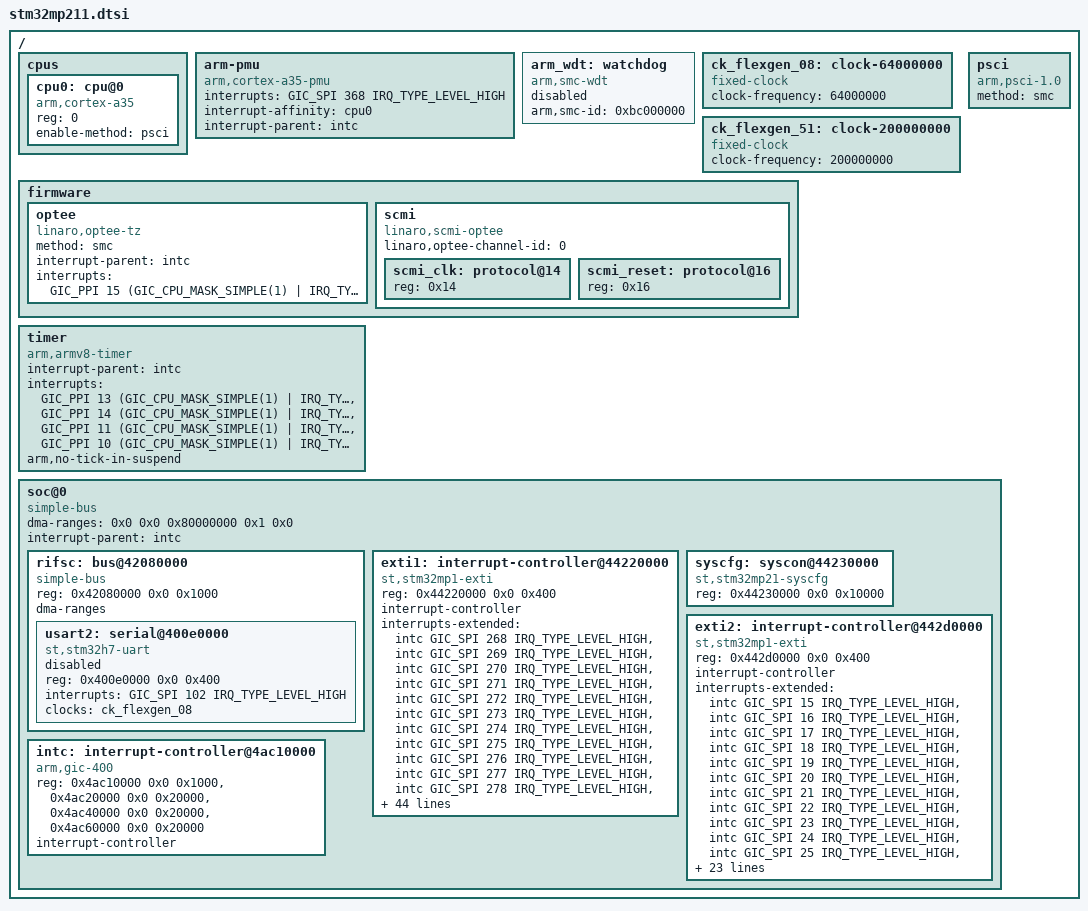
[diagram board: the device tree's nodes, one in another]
// SPDX-License-Identifier: (GPL-2.0-only OR BSD-3-Clause)
/*
 * Copyright (C) STMicroelectronics 2025 - All Rights Reserved
 * Author: Alexandre Torgue <alexandre.torgue@foss.st.com> for STMicroelectronics.
 */
#include <dt-bindings/interrupt-controller/arm-gic.h>

/ {
	#address-cells = <2>;
	#size-cells = <2>;

	cpus {
		#address-cells = <1>;
		#size-cells = <0>;

		cpu0: cpu@0 {
			compatible = "arm,cortex-a35";
			reg = <0>;
			device_type = "cpu";
			enable-method = "psci";
		};
	};

	arm-pmu {
		compatible = "arm,cortex-a35-pmu";
		interrupts = <GIC_SPI 368 IRQ_TYPE_LEVEL_HIGH>;
		interrupt-affinity = <&cpu0>;
		interrupt-parent = <&intc>;
	};

	arm_wdt: watchdog {
		compatible = "arm,smc-wdt";
		arm,smc-id = <0xbc000000>;
		status = "disabled";
	};

	ck_flexgen_08: clock-64000000 {
		compatible = "fixed-clock";
		#clock-cells = <0>;
		clock-frequency = <64000000>;
	};

	ck_flexgen_51: clock-200000000 {
		compatible = "fixed-clock";
		#clock-cells = <0>;
		clock-frequency = <200000000>;
	};

	firmware {
		optee {
			compatible = "linaro,optee-tz";
			method = "smc";
			interrupt-parent = <&intc>;
			interrupts = <GIC_PPI 15 (GIC_CPU_MASK_SIMPLE(1) | IRQ_TYPE_LEVEL_LOW)>;
		};

		scmi: scmi {
			compatible = "linaro,scmi-optee";
			#address-cells = <1>;
			#size-cells = <0>;
			linaro,optee-channel-id = <0>;

			scmi_clk: protocol@14 {
				reg = <0x14>;
				#clock-cells = <1>;
			};

			scmi_reset: protocol@16 {
				reg = <0x16>;
				#reset-cells = <1>;
			};
		};
	};

	psci {
		compatible = "arm,psci-1.0";
		method = "smc";
	};

	timer {
		compatible = "arm,armv8-timer";
		interrupt-parent = <&intc>;
		interrupts = <GIC_PPI 13 (GIC_CPU_MASK_SIMPLE(1) | IRQ_TYPE_LEVEL_LOW)>,
			     <GIC_PPI 14 (GIC_CPU_MASK_SIMPLE(1) | IRQ_TYPE_LEVEL_LOW)>,
			     <GIC_PPI 11 (GIC_CPU_MASK_SIMPLE(1) | IRQ_TYPE_LEVEL_LOW)>,
			     <GIC_PPI 10 (GIC_CPU_MASK_SIMPLE(1) | IRQ_TYPE_LEVEL_LOW)>;
		arm,no-tick-in-suspend;
	};

	soc@0 {
		compatible = "simple-bus";
		ranges = <0x0 0x0 0x0 0x0 0x80000000>;
		dma-ranges = <0x0 0x0 0x80000000 0x1 0x0>;
		interrupt-parent = <&intc>;
		#address-cells = <1>;
		#size-cells = <2>;

		rifsc: bus@42080000 {
			compatible = "simple-bus";
			reg = <0x42080000 0x0 0x1000>;
			ranges;
			dma-ranges;
			#address-cells = <1>;
			#size-cells = <2>;

			usart2: serial@400e0000 {
				compatible = "st,stm32h7-uart";
				reg = <0x400e0000 0x0 0x400>;
				interrupts = <GIC_SPI 102 IRQ_TYPE_LEVEL_HIGH>;
				clocks = <&ck_flexgen_08>;
				status = "disabled";
			};
		};

		exti1: interrupt-controller@44220000 {
			compatible = "st,stm32mp1-exti", "syscon";
			reg = <0x44220000 0x0 0x400>;
			interrupt-controller;
			#interrupt-cells = <2>;
			interrupts-extended =
				<&intc GIC_SPI 268 IRQ_TYPE_LEVEL_HIGH>,	/* EXTI_0 */
				<&intc GIC_SPI 269 IRQ_TYPE_LEVEL_HIGH>,
				<&intc GIC_SPI 270 IRQ_TYPE_LEVEL_HIGH>,
				<&intc GIC_SPI 271 IRQ_TYPE_LEVEL_HIGH>,
				<&intc GIC_SPI 272 IRQ_TYPE_LEVEL_HIGH>,
				<&intc GIC_SPI 273 IRQ_TYPE_LEVEL_HIGH>,
				<&intc GIC_SPI 274 IRQ_TYPE_LEVEL_HIGH>,
				<&intc GIC_SPI 275 IRQ_TYPE_LEVEL_HIGH>,
				<&intc GIC_SPI 276 IRQ_TYPE_LEVEL_HIGH>,
				<&intc GIC_SPI 277 IRQ_TYPE_LEVEL_HIGH>,
				<&intc GIC_SPI 278 IRQ_TYPE_LEVEL_HIGH>,	/* EXTI_10 */
				<&intc GIC_SPI 279 IRQ_TYPE_LEVEL_HIGH>,
				<&intc GIC_SPI 280 IRQ_TYPE_LEVEL_HIGH>,
				<&intc GIC_SPI 281 IRQ_TYPE_LEVEL_HIGH>,
				<&intc GIC_SPI 282 IRQ_TYPE_LEVEL_HIGH>,
				<&intc GIC_SPI 283 IRQ_TYPE_LEVEL_HIGH>,
				<&intc GIC_SPI 0   IRQ_TYPE_LEVEL_HIGH>,
				<&intc GIC_SPI 1   IRQ_TYPE_LEVEL_HIGH>,
				<&intc GIC_SPI 211 IRQ_TYPE_LEVEL_HIGH>,
				<&intc GIC_SPI 210 IRQ_TYPE_LEVEL_HIGH>,
				<0>,						/* EXTI_20 */
				<&intc GIC_SPI 95  IRQ_TYPE_LEVEL_HIGH>,
				<&intc GIC_SPI 97  IRQ_TYPE_LEVEL_HIGH>,
				<&intc GIC_SPI 124 IRQ_TYPE_LEVEL_HIGH>,
				<0>,
				<0>,
				<&intc GIC_SPI 101 IRQ_TYPE_LEVEL_HIGH>,
				<&intc GIC_SPI 102 IRQ_TYPE_LEVEL_HIGH>,
				<&intc GIC_SPI 103 IRQ_TYPE_LEVEL_HIGH>,
				<&intc GIC_SPI 123 IRQ_TYPE_LEVEL_HIGH>,
				<&intc GIC_SPI 113 IRQ_TYPE_LEVEL_HIGH>,	/* EXTI_30 */
				<&intc GIC_SPI 114 IRQ_TYPE_LEVEL_HIGH>,
				<&intc GIC_SPI 135 IRQ_TYPE_LEVEL_HIGH>,
				<0>,
				<0>,
				<0>,
				<&intc GIC_SPI 99  IRQ_TYPE_LEVEL_HIGH>,
				<&intc GIC_SPI 100 IRQ_TYPE_LEVEL_HIGH>,
				<&intc GIC_SPI 112 IRQ_TYPE_LEVEL_HIGH>,
				<&intc GIC_SPI 137 IRQ_TYPE_LEVEL_HIGH>,
				<&intc GIC_SPI 138 IRQ_TYPE_LEVEL_HIGH>,	/* EXTI_40 */
				<&intc GIC_SPI 139 IRQ_TYPE_LEVEL_HIGH>,
				<0>,
				<&intc GIC_SPI 150 IRQ_TYPE_LEVEL_HIGH>,
				<&intc GIC_SPI 158 IRQ_TYPE_LEVEL_HIGH>,
				<0>,
				<0>,
				<&intc GIC_SPI 149 IRQ_TYPE_LEVEL_HIGH>,
				<&intc GIC_SPI 180 IRQ_TYPE_LEVEL_HIGH>,
				<0>,
				<0>,						/* EXTI_50 */
				<0>,
				<0>,
				<0>,
				<0>,
				<0>,
				<0>,
				<0>,
				<0>,
				<&intc GIC_SPI 152 IRQ_TYPE_LEVEL_HIGH>,
				<0>,						/* EXTI_60 */
				<&intc GIC_SPI 154 IRQ_TYPE_LEVEL_HIGH>,
				<0>,
				<0>,
				<&intc GIC_SPI 185 IRQ_TYPE_LEVEL_HIGH>,
				<0>,
				<0>,
				<&intc GIC_SPI 9   IRQ_TYPE_LEVEL_HIGH>,
				<&intc GIC_SPI 118 IRQ_TYPE_LEVEL_HIGH>,
				<0>,
				<&intc GIC_SPI 121 IRQ_TYPE_LEVEL_HIGH>,	/* EXTI_70 */
				<0>,
				<&intc GIC_SPI 188 IRQ_TYPE_LEVEL_HIGH>,
				<&intc GIC_SPI 172 IRQ_TYPE_LEVEL_HIGH>,
				<&intc GIC_SPI 96  IRQ_TYPE_LEVEL_HIGH>,
				<&intc GIC_SPI 98  IRQ_TYPE_LEVEL_HIGH>,
				<&intc GIC_SPI 125 IRQ_TYPE_LEVEL_HIGH>,
				<&intc GIC_SPI 205 IRQ_TYPE_LEVEL_HIGH>,
				<&intc GIC_SPI 206 IRQ_TYPE_LEVEL_HIGH>,
				<&intc GIC_SPI 207 IRQ_TYPE_LEVEL_HIGH>;
		};

		syscfg: syscon@44230000 {
			compatible = "st,stm32mp21-syscfg", "syscon";
			reg = <0x44230000 0x0 0x10000>;
		};

		exti2: interrupt-controller@442d0000 {
			compatible = "st,stm32mp1-exti", "syscon";
			reg = <0x442d0000 0x0 0x400>;
			interrupt-controller;
			#interrupt-cells = <2>;
			interrupts-extended =
				<&intc GIC_SPI 15  IRQ_TYPE_LEVEL_HIGH>,	/* EXTI_0 */
				<&intc GIC_SPI 16  IRQ_TYPE_LEVEL_HIGH>,
				<&intc GIC_SPI 17  IRQ_TYPE_LEVEL_HIGH>,
				<&intc GIC_SPI 18  IRQ_TYPE_LEVEL_HIGH>,
				<&intc GIC_SPI 19  IRQ_TYPE_LEVEL_HIGH>,
				<&intc GIC_SPI 20  IRQ_TYPE_LEVEL_HIGH>,
				<&intc GIC_SPI 21  IRQ_TYPE_LEVEL_HIGH>,
				<&intc GIC_SPI 22  IRQ_TYPE_LEVEL_HIGH>,
				<&intc GIC_SPI 23  IRQ_TYPE_LEVEL_HIGH>,
				<&intc GIC_SPI 24  IRQ_TYPE_LEVEL_HIGH>,
				<&intc GIC_SPI 25  IRQ_TYPE_LEVEL_HIGH>,	/* EXTI_10 */
				<&intc GIC_SPI 26  IRQ_TYPE_LEVEL_HIGH>,
				<&intc GIC_SPI 27  IRQ_TYPE_LEVEL_HIGH>,
				<&intc GIC_SPI 28  IRQ_TYPE_LEVEL_HIGH>,
				<&intc GIC_SPI 29  IRQ_TYPE_LEVEL_HIGH>,
				<&intc GIC_SPI 30  IRQ_TYPE_LEVEL_HIGH>,
				<&intc GIC_SPI 10  IRQ_TYPE_LEVEL_HIGH>,
				<&intc GIC_SPI 11  IRQ_TYPE_LEVEL_HIGH>,
				<0>,
				<0>,
				<0>,						/* EXTI_20 */
				<&intc GIC_SPI 12  IRQ_TYPE_LEVEL_HIGH>,
				<&intc GIC_SPI 13  IRQ_TYPE_LEVEL_HIGH>,
				<0>,
				<0>,
				<0>,
				<&intc GIC_SPI 136 IRQ_TYPE_LEVEL_HIGH>,
				<0>,
				<0>,
				<&intc GIC_SPI 181 IRQ_TYPE_LEVEL_HIGH>,
				<&intc GIC_SPI 182 IRQ_TYPE_LEVEL_HIGH>,	/* EXTI_30 */
				<&intc GIC_SPI 183 IRQ_TYPE_LEVEL_HIGH>,
				<0>,
				<0>,
				<0>,
				<&intc GIC_SPI 5   IRQ_TYPE_LEVEL_HIGH>,
				<&intc GIC_SPI 4   IRQ_TYPE_LEVEL_HIGH>,
				<&intc GIC_SPI 6   IRQ_TYPE_LEVEL_HIGH>,
				<0>,
				<&intc GIC_SPI 2   IRQ_TYPE_LEVEL_HIGH>,
				<&intc GIC_SPI 3   IRQ_TYPE_LEVEL_HIGH>,	/* EXTI_40 */
				<0>,
				<0>,
				<0>,
				<0>,
				<0>,
				<0>,
				<0>,
				<0>,
				<&intc GIC_SPI 201 IRQ_TYPE_LEVEL_HIGH>,
				<0>,						/* EXTI_50 */
				<&intc GIC_SPI 202 IRQ_TYPE_LEVEL_HIGH>,
				<&intc GIC_SPI 203 IRQ_TYPE_LEVEL_HIGH>,
				<&intc GIC_SPI 204 IRQ_TYPE_LEVEL_HIGH>;
		};

		intc: interrupt-controller@4ac10000 {
			compatible = "arm,gic-400";
			reg = <0x4ac10000 0x0 0x1000>,
			      <0x4ac20000 0x0 0x20000>,
			      <0x4ac40000 0x0 0x20000>,
			      <0x4ac60000 0x0 0x20000>;
			      #interrupt-cells = <3>;
			      interrupt-controller;
		};
	};
};
